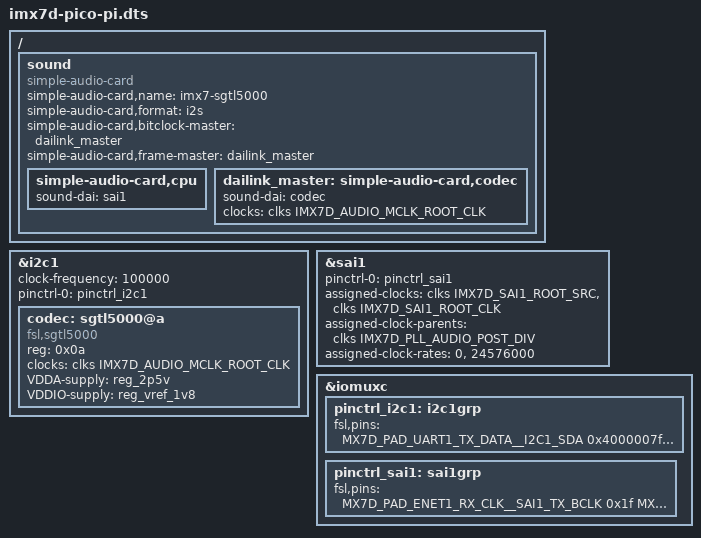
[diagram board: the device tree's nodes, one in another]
// SPDX-License-Identifier: (GPL-2.0+ OR MIT)
//
// Copyright 2017 NXP

#include "imx7d-pico.dtsi"

/ {
	sound {
		compatible = "simple-audio-card";
		simple-audio-card,name = "imx7-sgtl5000";
		simple-audio-card,format = "i2s";
		simple-audio-card,bitclock-master = <&dailink_master>;
		simple-audio-card,frame-master = <&dailink_master>;
		simple-audio-card,cpu {
			sound-dai = <&sai1>;
		};

		dailink_master: simple-audio-card,codec {
			sound-dai = <&codec>;
			clocks = <&clks IMX7D_AUDIO_MCLK_ROOT_CLK>;
		};
	};
};

&i2c1 {
	clock-frequency = <100000>;
	pinctrl-names = "default";
	pinctrl-0 = <&pinctrl_i2c1>;
	status = "okay";

	codec: sgtl5000@a {
		#sound-dai-cells = <0>;
		reg = <0x0a>;
		compatible = "fsl,sgtl5000";
		clocks = <&clks IMX7D_AUDIO_MCLK_ROOT_CLK>;
		VDDA-supply = <&reg_2p5v>;
		VDDIO-supply = <&reg_vref_1v8>;
	};
};

&sai1 {
	pinctrl-names = "default";
	pinctrl-0 = <&pinctrl_sai1>;
	assigned-clocks = <&clks IMX7D_SAI1_ROOT_SRC>,
			  <&clks IMX7D_SAI1_ROOT_CLK>;
	assigned-clock-parents = <&clks IMX7D_PLL_AUDIO_POST_DIV>;
	assigned-clock-rates = <0>, <24576000>;
	status = "okay";
};


&iomuxc {
	pinctrl_i2c1: i2c1grp {
		fsl,pins = <
			MX7D_PAD_UART1_TX_DATA__I2C1_SDA	0x4000007f
			MX7D_PAD_UART1_RX_DATA__I2C1_SCL	0x4000007f
		>;
	};

	pinctrl_sai1: sai1grp {
		fsl,pins = <
			MX7D_PAD_ENET1_RX_CLK__SAI1_TX_BCLK	0x1f
			MX7D_PAD_ENET1_CRS__SAI1_TX_SYNC	0x1f
			MX7D_PAD_ENET1_COL__SAI1_TX_DATA0	0x30
			MX7D_PAD_ENET1_TX_CLK__SAI1_RX_DATA0	0x1f
		>;
	};
};
